# N32G41x register map
Vendor: Nsingtech Ltd.; File version: 1.0
CPU: CM4 r0p1, little endian, no MPU, no FPU, 4 interrupt priority bits
Registers are 32-bit, read-write, reset 0x0 unless marked. A register's access mark holds for its fields unless they carry their own. Offsets are from the block's base; [hi:lo] are bit positions; {n}, {i} and the like mark numbered series.

## GTIM2 — General-purpose Timer 2
Base 0x40000400
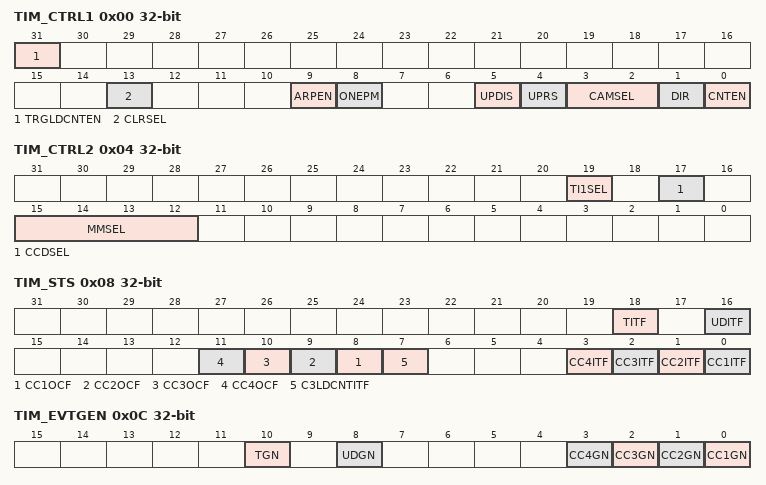
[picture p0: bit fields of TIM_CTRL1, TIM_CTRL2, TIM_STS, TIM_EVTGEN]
0x00 TIM_CTRL1 — TIM Control Register 1
  [31] TRGLDCNTEN — TRGI event trigger counter load LVR enable
  [13] CLRSEL — OCxRef selection
  [9] ARPEN — Auto-reload preload enable
  [8] ONEPM — One pulse mode
  [5] UPDIS — Update disable
  [4] UPRS — Update request source
  [3:2] CAMSEL — Center-aligned mode selection
  [1] DIR — Direction
  [0] CNTEN — Counter enable
0x04 TIM_CTRL2 — TIM Control Register 2
  [19] TI1SEL — TI1 selection
  [17] CCDSEL — Capture/compare DMA selection
  [15:12] MMSEL — Master mode selection
0x08 TIM_STS — TIM Status Register
  [18] TITF — Trigger interrupt flag
  [16] UDITF — Update interrupt flag
  [n+7] CC{n}OCF (n=1..4) — Capture/Compare {n} overcapture flag
  [7] C3LDCNTITF — TI3 event load LVR interrupt flag
  [n-1] CC{n}ITF (n=1..4) — Capture/Compare {n} interrupt flag
0x0C TIM_EVTGEN wo — TIM Event Generation Register
  [10] TGN — Trigger generation
  [8] UDGN — Update generation
  [n-1] CC{n}GN (n=1..4) — Capture/Compare {n} generation
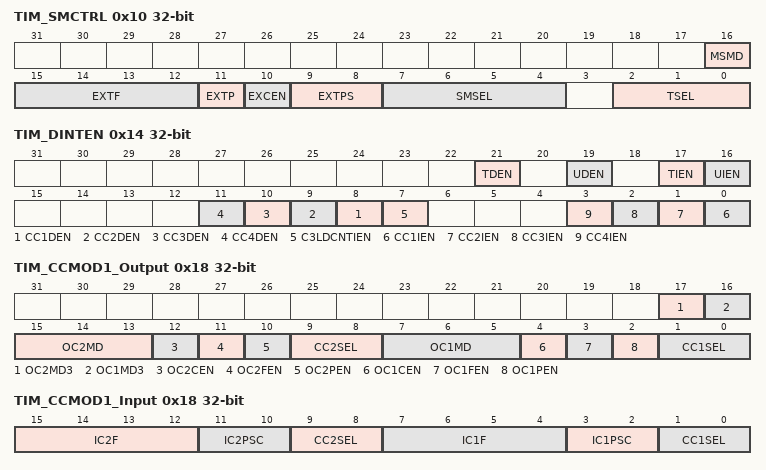
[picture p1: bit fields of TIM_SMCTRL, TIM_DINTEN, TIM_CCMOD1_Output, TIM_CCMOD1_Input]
0x10 TIM_SMCTRL — TIM Slave Mode Control Register
  [16] MSMD — Master/slave mode
  [15:12] EXTF — External trigger filter
  [11] EXTP — External trigger polarity
  [10] EXCEN — External clock enable
  [9:8] EXTPS — External trigger prescaler
  [7:4] SMSEL — Slave mode selection
  [2:0] TSEL — Trigger selection
0x14 TIM_DINTEN — TIM DMA/Interrupt Enable Register
  [21] TDEN — Trigger DMA request enable
  [19] UDEN — Update DMA request enable
  [17] TIEN — Trigger interrupt enable
  [16] UIEN — Update interrupt enable
  [n+7] CC{n}DEN (n=1..4) — Capture/Compare {n} DMA request enable
  [7] C3LDCNTIEN — TI3 event load LVR interrupt enable
  [n-1] CC{n}IEN (n=1..4) — Capture/Compare {n} interrupt enable
0x18 TIM_CCMOD1_Output — TIM Capture/Compare Mode Register 1 Output
  [17] OC2MD3 — Output compare 2 mode bit3
  [16] OC1MD3 — Output compare 1 mode bit3
  [15:13] OC2MD — Output compare 2 mode
  [12] OC2CEN — OC2 clear enable
  [11] OC2FEN — OC2 fast enable
  [10] OC2PEN — OC2 preload enable
  [9:8] CC2SEL — Capture/Compare 2 selection
  [7:5] OC1MD — Output compare 1 mode
  [4] OC1CEN — OC1 clear enable
  [3] OC1FEN — OC1 fast enable
  [2] OC1PEN — OC1 preload enable
  [1:0] CC1SEL — Capture/Compare 1 selection
0x18 TIM_CCMOD1_Input (alternate view of TIM_CCMOD1_Output) — TIM Capture/Compare Mode Register 1 Input
  [15:12] IC2F — Input capture 2 filter
  [11:10] IC2PSC — Input capture 2 prescaler
  [9:8] CC2SEL — Capture/Compare 2 selection
  [7:4] IC1F — Input capture 1 filter
  [3:2] IC1PSC — Input capture 1 prescaler
  [1:0] CC1SEL — Capture/Compare 1 selection
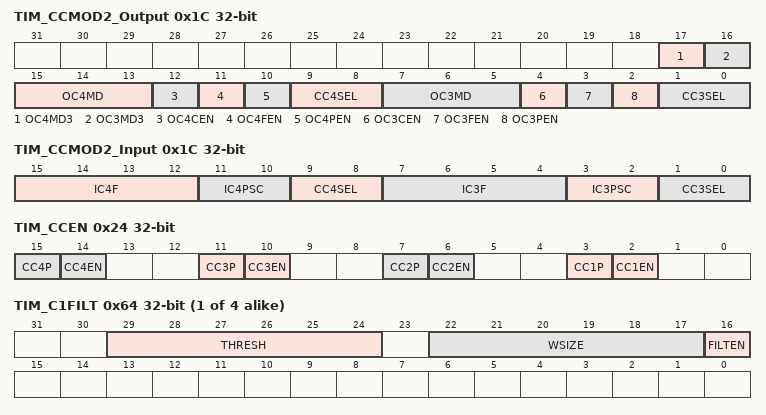
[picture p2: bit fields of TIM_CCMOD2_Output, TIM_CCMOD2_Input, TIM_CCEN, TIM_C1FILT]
0x1C TIM_CCMOD2_Output — TIM Capture/Compare Mode Register 2 Output
  [17] OC4MD3 — Output compare 4 mode bit3
  [16] OC3MD3 — Output compare 3 mode bit3
  [15:13] OC4MD — Output compare 4 mode
  [12] OC4CEN — OC4 clear enable
  [11] OC4FEN — OC4 fast enable
  [10] OC4PEN — OC4 preload enable
  [9:8] CC4SEL — Capture/Compare 4 selection
  [7:5] OC3MD — Output compare 3 mode
  [4] OC3CEN — OC3 clear enable
  [3] OC3FEN — OC3 fast enable
  [2] OC3PEN — OC3 preload enable
  [1:0] CC3SEL — Capture/Compare 3 selection
0x1C TIM_CCMOD2_Input (alternate view of TIM_CCMOD2_Output) — TIM Capture/Compare Mode Register 2 Input
  [15:12] IC4F — Input capture 4 filter
  [11:10] IC4PSC — Input capture 4 prescaler
  [9:8] CC4SEL — Capture/Compare 4 selection
  [7:4] IC3F — Input capture 3 filter
  [3:2] IC3PSC — Input capture 3 prescaler
  [1:0] CC3SEL — Capture/Compare 3 selection
0x24 TIM_CCEN — TIM Capture/Compare Enable Register
  [4n-1] CC{n}P (n=1..4) — Capture/Compare {n} output polarity
  [4n-2] CC{n}EN (n=1..4) — Capture/Compare {n} output enable
{0x24+4i} TIM_CCDAT{i} (i=1..4) — TIM Capture/Compare Register {i}
  [15:0] CCDAT{i} — Capture/Compare value
0x40 TIM_PSC — TIM Prescaler Register
  [15:0] PSC — Prescaler value
0x44 TIM_AR reset 0xFFFFFFFF — TIM Auto-Reload Register
  [15:0] AR — Auto-reload value
0x48 TIM_CNT — TIM Counter Register
  [15:0] CNT — Counter value
{0x60+4i} TIM_C{i}FILT (i=1..4) — TIM Channel {i} Filter Register
  [29:24] THRESH — Threshold
  [22:17] WSIZE — Window size
  [16] FILTEN — Filter enable
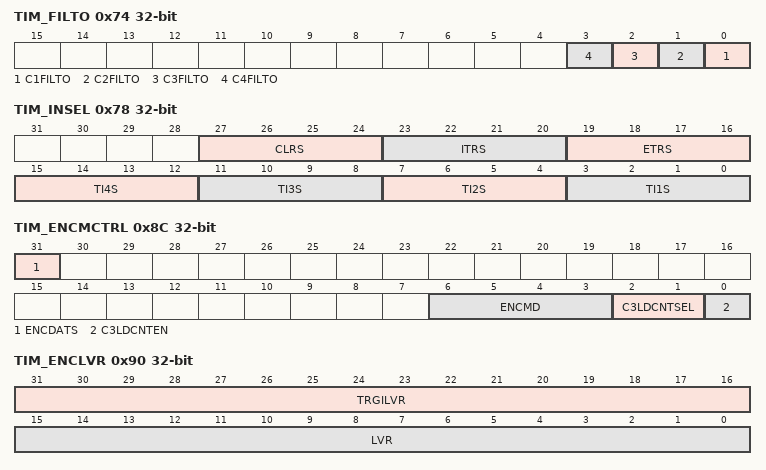
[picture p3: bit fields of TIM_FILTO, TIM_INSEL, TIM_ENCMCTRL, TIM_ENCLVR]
0x74 TIM_FILTO ro — TIM Filter Output Register
  [n-1] C{n}FILTO (n=1..4) — Channel {n} filter output status
0x78 TIM_INSEL — TIM Input Selection Register
  [27:24] CLRS — Select tim_ocref_clr input
  [23:20] ITRS — Select tim_itr input
  [19:16] ETRS — Select tim_etr input
  [4n-1:4n-4] TI{n}S (n=1..4) — Select tim_ti{n} input
0x88 TIM_ENCDAT ro — TIM Encoder Capture Data Register
  [15:0] ENCDAT — Encoder capture data
0x8C TIM_ENCMCTRL — TIM Encoder Mode Control Register
  [31] ENCDATS ro — Encoder capture data sign
  [6:3] ENCMD — Encoder mode selection
  [2:1] C3LDCNTSEL — TI3 event selection
  [0] C3LDCNTEN — TI3 event load LVR enable
0x90 TIM_ENCLVR — TIM Encoder Load Value Register
  [31:16] TRGILVR — TRGI load value
  [15:0] LVR — TI3 load value
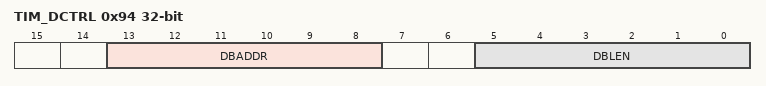
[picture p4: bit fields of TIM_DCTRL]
0x94 TIM_DCTRL — TIM DMA Control Register
  [13:8] DBADDR — DMA base address
  [5:0] DBLEN — DMA burst length
0x98 TIM_DADDR — TIM DMA Address Register
  [31:0] BURST — DMA access buffer

## GTIM1 — General-purpose Timer 1
Base 0x40000000
Registers as GTIM2; these are added or differ:
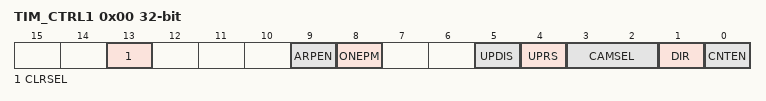
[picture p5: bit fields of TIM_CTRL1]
0x00 TIM_CTRL1 — TIM Control Register 1
  [13] CLRSEL — OCxRef selection
  [9] ARPEN — Auto-reload preload enable
  [8] ONEPM — One pulse mode
  [5] UPDIS — Update disable
  [4] UPRS — Update request source
  [3:2] CAMSEL — Center-aligned mode selection
  [1] DIR — Direction
  [0] CNTEN — Counter enable
{0x24+4i} TIM_CCDAT{i} (i=1..4) — TIM Capture/Compare Register {i}
  [31:0] CCDAT{i} — Capture/Compare value
0x44 TIM_AR reset 0xFFFFFFFF — TIM Auto-Reload Register
  [31:0] AR — Auto-reload value
0x48 TIM_CNT — TIM Counter Register
  [31:0] CNT — Counter value
0x88 TIM_ENCDAT ro — TIM Encoder Capture Data Register
  [31:0] ENCDAT — Encoder capture data
0x90 TIM_ENCLVR — TIM Encoder Load Value Register
  [31:0] LVR — TI3 load value
